# ATSAMA5D28CLD1G device description
Architecture: CORTEX-A5; Family: SAMA5; Series: SAMA5D2
Registers are 32-bit, read-write, no defined reset value unless marked. A register's access mark holds for its fields unless they carry their own. Offsets are from the block's base; [hi:lo] are bit positions.

## UART — Universal Asynchronous Receiver Transmitter
Instances: UART0 0xF801C000, UART1 0xF8020000, UART2 0xF8024000, UART3 0xFC008000, UART4 0xFC00C000
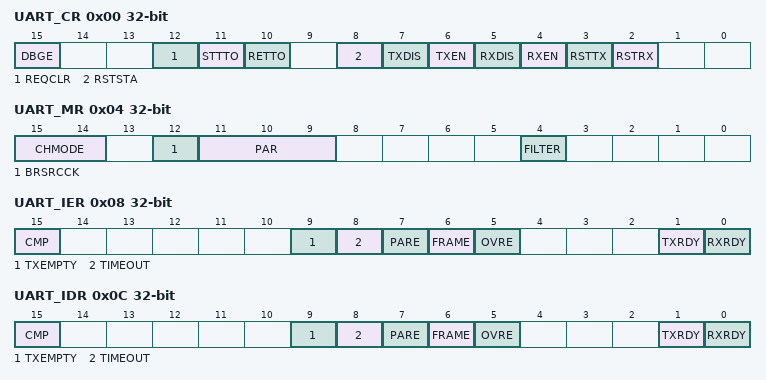
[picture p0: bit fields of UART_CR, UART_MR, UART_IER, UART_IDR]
0x00 UART_CR wo — Control Register
  [15] DBGE — Debug Enable
  [12] REQCLR — Request Clear
  [11] STTTO — Start Time-out
  [10] RETTO — Rearm Time-out
  [8] RSTSTA — Reset Status
  [7] TXDIS — Transmitter Disable
  [6] TXEN — Transmitter Enable
  [5] RXDIS — Receiver Disable
  [4] RXEN — Receiver Enable
  [3] RSTTX — Reset Transmitter
  [2] RSTRX — Reset Receiver
0x04 UART_MR — Mode Register
  [15:14] CHMODE — Channel Mode
    0=NORMAL (Normal mode); 1=AUTOMATIC (Automatic echo); 2=LOCAL_LOOPBACK; 3=REMOTE_LOOPBACK
  [12] BRSRCCK — Baud Rate Source Clock
    0=PERIPH_CLK (The baud rate is driven by the peripheral clock); 1=GCLK (The baud rate is driven by a PMC-programmable clock GCLK (see section Power Management Controller (PMC)).)
  [11:9] PAR — Parity Type
    0=EVEN (Even Parity); 1=ODD (Odd Parity); 2=SPACE (Space: parity forced to 0); 3=MARK (Mark: parity forced to 1); 4=NO (No parity)
  [4] FILTER — Receiver Digital Filter
    0=DISABLED (UART does not filter the receive line.); 1=ENABLED (UART filters the receive line using a three-sample filter (16x-bit clock) (2 over 3 majority).)
0x08 UART_IER wo (atomic set of UART_IMR) — Interrupt Enable Register
  [15] CMP — Enable Comparison Interrupt
  [9] TXEMPTY — Enable TXEMPTY Interrupt
  [8] TIMEOUT — Enable Time-out Interrupt
  [7] PARE — Enable Parity Error Interrupt
  [6] FRAME — Enable Framing Error Interrupt
  [5] OVRE — Enable Overrun Error Interrupt
  [1] TXRDY — Enable TXRDY Interrupt
  [0] RXRDY — Enable RXRDY Interrupt
0x0C UART_IDR wo (atomic clear of UART_IMR) — Interrupt Disable Register
  [15] CMP — Disable Comparison Interrupt
  [9] TXEMPTY — Disable TXEMPTY Interrupt
  [8] TIMEOUT — Disable Time-out Interrupt
  [7] PARE — Disable Parity Error Interrupt
  [6] FRAME — Disable Framing Error Interrupt
  [5] OVRE — Disable Overrun Error Interrupt
  [1] TXRDY — Disable TXRDY Interrupt
  [0] RXRDY — Disable RXRDY Interrupt
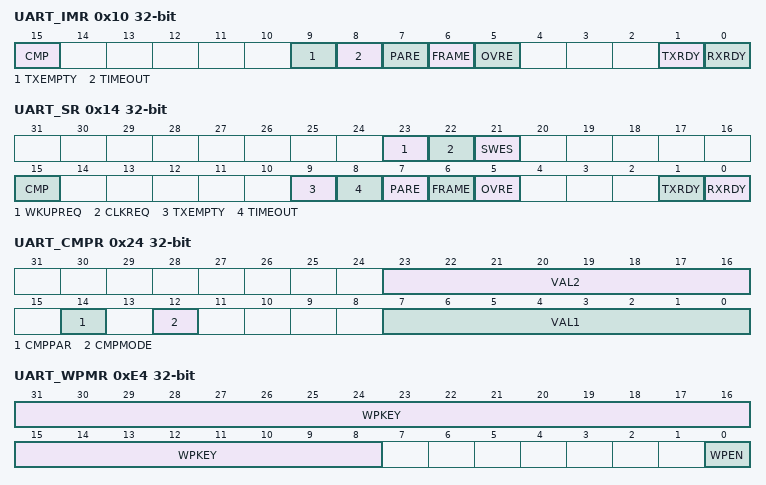
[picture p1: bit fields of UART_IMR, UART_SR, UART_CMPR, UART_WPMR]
0x10 UART_IMR ro (atomic read) — Interrupt Mask Register
  [15] CMP — Mask Comparison Interrupt
  [9] TXEMPTY — Mask TXEMPTY Interrupt
  [8] TIMEOUT — Mask Time-out Interrupt
  [7] PARE — Mask Parity Error Interrupt
  [6] FRAME — Mask Framing Error Interrupt
  [5] OVRE — Mask Overrun Error Interrupt
  [1] TXRDY — Disable TXRDY Interrupt
  [0] RXRDY — Mask RXRDY Interrupt
0x14 UART_SR ro — Status Register
  [23] WKUPREQ — Wake-Up Request
  [22] CLKREQ — Clock Request
  [21] SWES — SleepWalking Enable Status
  [15] CMP — Comparison Match
  [9] TXEMPTY — Transmitter Empty
  [8] TIMEOUT — Receiver Time-out
  [7] PARE — Parity Error
  [6] FRAME — Framing Error
  [5] OVRE — Overrun Error
  [1] TXRDY — Transmitter Ready
  [0] RXRDY — Receiver Ready
0x18 UART_RHR ro — Receive Holding Register
  [7:0] RXCHR — Received Character
0x1C UART_THR wo — Transmit Holding Register
  [7:0] TXCHR — Character to be Transmitted
0x20 UART_BRGR — Baud Rate Generator Register
  [15:0] CD — Clock Divisor
0x24 UART_CMPR — Comparison Register
  [23:16] VAL2 — Second Comparison Value for Received Character
  [14] CMPPAR — Compare Parity
  [12] CMPMODE — Comparison Mode
    0=FLAG_ONLY (Any character is received and comparison function drives CMP flag.); 1=START_CONDITION (Comparison condition must be met to start reception.)
  [7:0] VAL1 — First Comparison Value for Received Character
0x28 UART_RTOR — Receiver Time-out Register
  [7:0] TO — Time-out Value
0xE4 UART_WPMR — Write Protection Mode Register
  [31:8] WPKEY — Write Protection Key
    0x554152=PASSWD (Writing any other value in this field aborts the write operation.Always reads as 0.)
  [0] WPEN — Write Protection Enable
